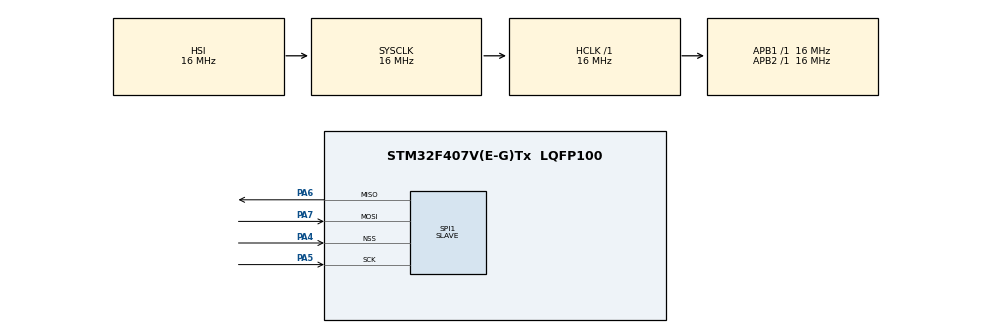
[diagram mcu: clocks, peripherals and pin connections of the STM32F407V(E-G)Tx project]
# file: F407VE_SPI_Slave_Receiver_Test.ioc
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Mcu.Family=STM32F4
Mcu.Name=STM32F407V(E-G)Tx
Mcu.Package=LQFP100
NVIC.PriorityGroup=NVIC_PRIORITYGROUP_4
NVIC.SPI1_IRQn=true\:1\:0\:true\:false\:true\:true\:true
PA13.Mode=Trace_Asynchronous_SW
PA13.Signal=SYS_JTMS-SWDIO
PA14.Mode=Trace_Asynchronous_SW
PA14.Signal=SYS_JTCK-SWCLK
PA4.Mode=NSS_Signal_Hard_Input
PA4.Signal=SPI1_NSS
PA5.Mode=Full_Duplex_Slave
PA5.Signal=SPI1_SCK
PA6.Mode=Full_Duplex_Slave
PA6.Signal=SPI1_MISO
PA7.Mode=Full_Duplex_Slave
PA7.Signal=SPI1_MOSI
PB3.Mode=Trace_Asynchronous_SW
PB3.Signal=SYS_JTDO-SWO
PH0-OSC_IN.Mode=HSE-External-Oscillator
PH0-OSC_IN.Signal=RCC_OSC_IN
PH1-OSC_OUT.Mode=HSE-External-Oscillator
PH1-OSC_OUT.Signal=RCC_OSC_OUT
ProjectManager.HeapSize=0x200
ProjectManager.StackSize=0x400
ProjectManager.TargetToolchain=STM32CubeIDE
RCC.AHBFreq_Value=16000000
RCC.APB1Freq_Value=16000000
RCC.APB2Freq_Value=16000000
RCC.CortexFreq_Value=16000000
RCC.HSE_VALUE=25000000
RCC.HSI_VALUE=16000000
RCC.LSE_VALUE=32768
RCC.SYSCLKFreq_VALUE=16000000
RCC.VCOOutputFreq_Value=192000000
SPI1.Direction=SPI_DIRECTION_2LINES
SPI1.Mode=SPI_MODE_SLAVE
SPI1.VirtualNSS=VM_NSSHARD
SPI1.VirtualType=VM_SLAVE
board=custom

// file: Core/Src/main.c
/* USER CODE BEGIN Header */
/**
  ******************************************************************************
  * @file           : main.c
  * @brief          : Main program body
  ******************************************************************************
  * @attention
  *
  * <h2><center>&copy; Copyright (c) 2020 STMicroelectronics.
  * All rights reserved.</center></h2>
  *
  * This software component is licensed by ST under BSD 3-Clause license,
  * the "License"; You may not use this file except in compliance with the
  * License. You may obtain a copy of the License at:
  *                        opensource.org/licenses/BSD-3-Clause
  *
  ******************************************************************************
  */
/* USER CODE END Header */

#include "main.h"

/* USER CODE BEGIN Includes */
#include <stdio.h>
/* USER CODE END Includes */

SPI_HandleTypeDef hspi1;

/* USER CODE BEGIN PV */
uint8_t spi_rev_data = 49;
uint8_t spi_send_data = 48;
/* USER CODE END PV */

void SystemClock_Config(void);
static void MX_GPIO_Init(void);
static void MX_SPI1_Init(void);

int main(void)
{

  /* MCU Configuration--------------------------------------------------------*/

  /* Reset of all peripherals, Initializes the Flash interface and the Systick. */
  HAL_Init();

  /* Configure the system clock */
  SystemClock_Config();

  /* Initialize all configured peripherals */
  MX_GPIO_Init();
  MX_SPI1_Init();
  /* USER CODE BEGIN 2 */
  HAL_SPI_Receive_IT(&hspi1, &spi_rev_data, 1);
  /* USER CODE END 2 */

  /* Infinite loop */
  /* USER CODE BEGIN WHILE */
  while (1)
  {
	  HAL_Delay(1);
    /* USER CODE END WHILE */

  }
}

void SystemClock_Config(void)
{
  RCC_OscInitTypeDef RCC_OscInitStruct = {0};
  RCC_ClkInitTypeDef RCC_ClkInitStruct = {0};

  /** Configure the main internal regulator output voltage
  */
  __HAL_RCC_PWR_CLK_ENABLE();
  __HAL_PWR_VOLTAGESCALING_CONFIG(PWR_REGULATOR_VOLTAGE_SCALE1);
  /** Initializes the CPU, AHB and APB busses clocks
  */
  RCC_OscInitStruct.OscillatorType = RCC_OSCILLATORTYPE_HSI;
  RCC_OscInitStruct.HSIState = RCC_HSI_ON;
  RCC_OscInitStruct.HSICalibrationValue = RCC_HSICALIBRATION_DEFAULT;
  RCC_OscInitStruct.PLL.PLLState = RCC_PLL_NONE;
  if (HAL_RCC_OscConfig(&RCC_OscInitStruct) != HAL_OK)
  {
    Error_Handler();
  }
  /** Initializes the CPU, AHB and APB busses clocks
  */
  RCC_ClkInitStruct.ClockType = RCC_CLOCKTYPE_HCLK|RCC_CLOCKTYPE_SYSCLK
                              |RCC_CLOCKTYPE_PCLK1|RCC_CLOCKTYPE_PCLK2;
  RCC_ClkInitStruct.SYSCLKSource = RCC_SYSCLKSOURCE_HSI;
  RCC_ClkInitStruct.AHBCLKDivider = RCC_SYSCLK_DIV1;
  RCC_ClkInitStruct.APB1CLKDivider = RCC_HCLK_DIV1;
  RCC_ClkInitStruct.APB2CLKDivider = RCC_HCLK_DIV1;

  if (HAL_RCC_ClockConfig(&RCC_ClkInitStruct, FLASH_LATENCY_0) != HAL_OK)
  {
    Error_Handler();
  }
}

static void MX_SPI1_Init(void)
{

  /* SPI1 parameter configuration*/
  hspi1.Instance = SPI1;
  hspi1.Init.Mode = SPI_MODE_SLAVE;
  hspi1.Init.Direction = SPI_DIRECTION_2LINES;
  hspi1.Init.DataSize = SPI_DATASIZE_8BIT;
  hspi1.Init.CLKPolarity = SPI_POLARITY_LOW;
  hspi1.Init.CLKPhase = SPI_PHASE_1EDGE;
  hspi1.Init.NSS = SPI_NSS_HARD_INPUT;
  hspi1.Init.FirstBit = SPI_FIRSTBIT_MSB;
  hspi1.Init.TIMode = SPI_TIMODE_DISABLE;
  hspi1.Init.CRCCalculation = SPI_CRCCALCULATION_DISABLE;
  hspi1.Init.CRCPolynomial = 10;
  if (HAL_SPI_Init(&hspi1) != HAL_OK)
  {
    Error_Handler();
  }

}

static void MX_GPIO_Init(void)
{

  /* GPIO Ports Clock Enable */
  __HAL_RCC_GPIOH_CLK_ENABLE();
  __HAL_RCC_GPIOA_CLK_ENABLE();
  __HAL_RCC_GPIOB_CLK_ENABLE();

}

/* USER CODE BEGIN 4 */
int _write(int file, char *ptr, int len)
{
  /* Implement your write code here, this is used by puts and printf for example */
  int i=0;
  for(i=0 ; i<len ; i++)
    ITM_SendChar((*ptr++));
  return len;
}

void HAL_SPI_RxCpltCallback(SPI_HandleTypeDef *hspi)
{
	printf("%d X	\r\n", spi_rev_data);
	HAL_SPI_Receive_IT(hspi, &spi_rev_data, 1);
}
/* USER CODE END 4 */

void Error_Handler(void)
{
}

/************************ (C) COPYRIGHT STMicroelectronics *****END OF FILE****/
